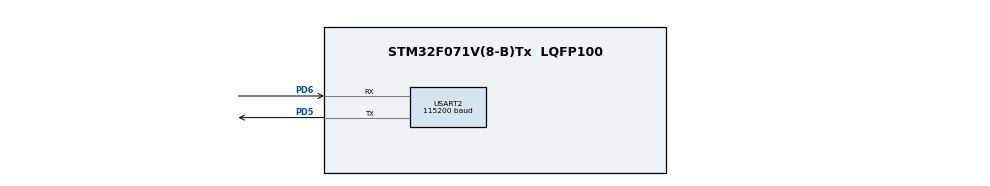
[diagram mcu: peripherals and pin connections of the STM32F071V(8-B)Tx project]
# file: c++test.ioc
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Mcu.Family=STM32F0
Mcu.Name=STM32F071V(8-B)Tx
Mcu.Package=LQFP100
PD5.Mode=Asynchronous
PD5.Signal=USART2_TX
PD6.Mode=Asynchronous
PD6.Signal=USART2_RX
PF0-OSC_IN.Mode=HSE-External-Oscillator
PF0-OSC_IN.Signal=RCC_OSC_IN
PF1-OSC_OUT.Mode=HSE-External-Oscillator
PF1-OSC_OUT.Signal=RCC_OSC_OUT
ProjectManager.HeapSize=0x200
ProjectManager.StackSize=0x400
ProjectManager.TargetToolchain=MDK-ARM V5.27
RCC.AHBFreq_Value=48000000
RCC.APB1Freq_Value=48000000
RCC.APB1TimFreq_Value=48000000
RCC.HCLKFreq_Value=48000000
RCC.PLLMUL=RCC_PLL_MUL6
RCC.SYSCLKFreq_VALUE=48000000
RCC.SYSCLKSource=RCC_SYSCLKSOURCE_PLLCLK
USART2.BaudRate=115200
USART2.VirtualMode-Asynchronous=VM_ASYNC
board=custom

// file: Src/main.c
/* USER CODE BEGIN Header */
/**
  ******************************************************************************
  * @file           : main.c
  * @brief          : Main program body
  ******************************************************************************
  * @attention
  *
  * <h2><center>&copy; Copyright (c) 2020 STMicroelectronics.
  * All rights reserved.</center></h2>
  *
  * This software component is licensed by ST under BSD 3-Clause license,
  * the "License"; You may not use this file except in compliance with the
  * License. You may obtain a copy of the License at:
  *                        opensource.org/licenses/BSD-3-Clause
  *
  ******************************************************************************
  */
/* USER CODE END Header */

#include "main.h"

void SystemClock_Config(void);
static void MX_GPIO_Init(void);
static void MX_USART2_UART_Init(void);
int main(void);

/* USER CODE BEGIN 0 */
#if 1
/*在初始化之前再初始化一些外设 目前暂无用*/
//extern void $Super$$__rt_entry(void);
//void $Sub$$__rt_entry(void)  {
//  MX_USART2_UART_Init();
//  $Super$$__rt_entry();
//}
//void __rt_entry(void)
//{
//}
#include <iostream>
#include "stdio.h"
namespace STM32_TEST {
using std::cout;
using std::endl;
TestGPIO::TestGPIO()
{
	cout<<"hello this is a test"<<endl;
	printf("hello this is a test\r\n");
}
TestGPIO::TestGPIO(uint16_t value)
{
	this->value = value;
	cout<<"hello this is a test value"<<endl;
	printf("hello this is a test value\r\n");

}
void TestGPIO::GPIOINIT(void)
{
  MX_GPIO_Init();
  MX_USART2_UART_Init();
}
void TestGPIO::SetGpio(int values)
{
	if(values==1)
	{
		GPIOC->BSRR |= GPIO_BSRR_BS_9;
		GPIOD->BSRR |= GPIO_BSRR_BS_11;
	}
	else
	{
		GPIOC->BRR |= GPIO_BSRR_BS_9;
		GPIOD->BRR |= GPIO_BSRR_BS_11;
	}

}
} /* namespace stm32 */

using STM32_TEST::TestGPIO;
#endif
/* USER CODE END 0 */

int main(void)
{
 TestGPIO testg;

  /* MCU Configuration--------------------------------------------------------*/

  /* Reset of all peripherals, Initializes the Flash interface and the Systick. */

  LL_APB1_GRP2_EnableClock(LL_APB1_GRP2_PERIPH_SYSCFG);
  LL_APB1_GRP1_EnableClock(LL_APB1_GRP1_PERIPH_PWR);

  /* System interrupt init*/

  /* Configure the system clock */
  SystemClock_Config();

  /* Initialize all configured peripherals */
//  MX_GPIO_Init();
//  MX_USART2_UART_Init();
	testg.GPIOINIT();
  /* USER CODE BEGIN 2 */
	uint16_t i =0;
  /* USER CODE END 2 */

  /* Infinite loop */
  while (1)
  {

    /* USER CODE BEGIN 3 */
	testg.SetGpio(i);
	i++;
	if(i>8)i=0;
	LL_mDelay(100);
  }
  /* USER CODE END 3 */
}

void SystemClock_Config(void)
{
  LL_FLASH_SetLatency(LL_FLASH_LATENCY_1);

  if(LL_FLASH_GetLatency() != LL_FLASH_LATENCY_1)
  {
  Error_Handler();
  }
  LL_RCC_HSI_Enable();

   /* Wait till HSI is ready */
  while(LL_RCC_HSI_IsReady() != 1)
  {

  }
  LL_RCC_HSI_SetCalibTrimming(16);
  LL_RCC_PLL_ConfigDomain_SYS(LL_RCC_PLLSOURCE_HSI, LL_RCC_PLL_MUL_6, LL_RCC_PREDIV_DIV_1);
  LL_RCC_PLL_Enable();

   /* Wait till PLL is ready */
  while(LL_RCC_PLL_IsReady() != 1)
  {

  }
  LL_RCC_SetAHBPrescaler(LL_RCC_SYSCLK_DIV_1);
  LL_RCC_SetAPB1Prescaler(LL_RCC_APB1_DIV_1);
  LL_RCC_SetSysClkSource(LL_RCC_SYS_CLKSOURCE_PLL);

   /* Wait till System clock is ready */
  while(LL_RCC_GetSysClkSource() != LL_RCC_SYS_CLKSOURCE_STATUS_PLL)
  {

  }
  LL_Init1msTick(48000000);
  LL_SYSTICK_SetClkSource(LL_SYSTICK_CLKSOURCE_HCLK);
  LL_SetSystemCoreClock(48000000);
  LL_RCC_SetUSARTClockSource(LL_RCC_USART2_CLKSOURCE_PCLK1);
}

static void MX_USART2_UART_Init(void)
{

  LL_USART_InitTypeDef USART_InitStruct = {0};

  LL_GPIO_InitTypeDef GPIO_InitStruct = {0};

  /* Peripheral clock enable */
  LL_APB1_GRP1_EnableClock(LL_APB1_GRP1_PERIPH_USART2);

  LL_AHB1_GRP1_EnableClock(LL_AHB1_GRP1_PERIPH_GPIOD);
  /**USART2 GPIO Configuration
  PD5   ------> USART2_TX
  PD6   ------> USART2_RX
  */
  GPIO_InitStruct.Pin = LL_GPIO_PIN_5;
  GPIO_InitStruct.Mode = LL_GPIO_MODE_ALTERNATE;
  GPIO_InitStruct.Speed = LL_GPIO_SPEED_FREQ_HIGH;
  GPIO_InitStruct.OutputType = LL_GPIO_OUTPUT_PUSHPULL;
  GPIO_InitStruct.Pull = LL_GPIO_PULL_NO;
  GPIO_InitStruct.Alternate = LL_GPIO_AF_0;
  LL_GPIO_Init(GPIOD, &GPIO_InitStruct);

  GPIO_InitStruct.Pin = LL_GPIO_PIN_6;
  GPIO_InitStruct.Mode = LL_GPIO_MODE_ALTERNATE;
  GPIO_InitStruct.Speed = LL_GPIO_SPEED_FREQ_HIGH;
  GPIO_InitStruct.OutputType = LL_GPIO_OUTPUT_PUSHPULL;
  GPIO_InitStruct.Pull = LL_GPIO_PULL_NO;
  GPIO_InitStruct.Alternate = LL_GPIO_AF_0;
  LL_GPIO_Init(GPIOD, &GPIO_InitStruct);

  USART_InitStruct.BaudRate = 115200;
  USART_InitStruct.DataWidth = LL_USART_DATAWIDTH_8B;
  USART_InitStruct.StopBits = LL_USART_STOPBITS_1;
  USART_InitStruct.Parity = LL_USART_PARITY_NONE;
  USART_InitStruct.TransferDirection = LL_USART_DIRECTION_TX_RX;
  USART_InitStruct.HardwareFlowControl = LL_USART_HWCONTROL_NONE;
  USART_InitStruct.OverSampling = LL_USART_OVERSAMPLING_16;
  LL_USART_Init(USART2, &USART_InitStruct);
  LL_USART_DisableIT_CTS(USART2);
  LL_USART_ConfigAsyncMode(USART2);
  LL_USART_Enable(USART2);

}

static void MX_GPIO_Init(void)
{

  /* GPIO Ports Clock Enable */
  LL_AHB1_GRP1_EnableClock(LL_AHB1_GRP1_PERIPH_GPIOF);
  LL_AHB1_GRP1_EnableClock(LL_AHB1_GRP1_PERIPH_GPIOD);
	GPIOD->MODER |=	GPIO_MODER_MODER11_0;
	GPIOC->MODER |=	GPIO_MODER_MODER9_0;
}

ARMAPI void Error_Handler(void)
{
}

/************************ (C) COPYRIGHT STMicroelectronics *****END OF FILE****/
